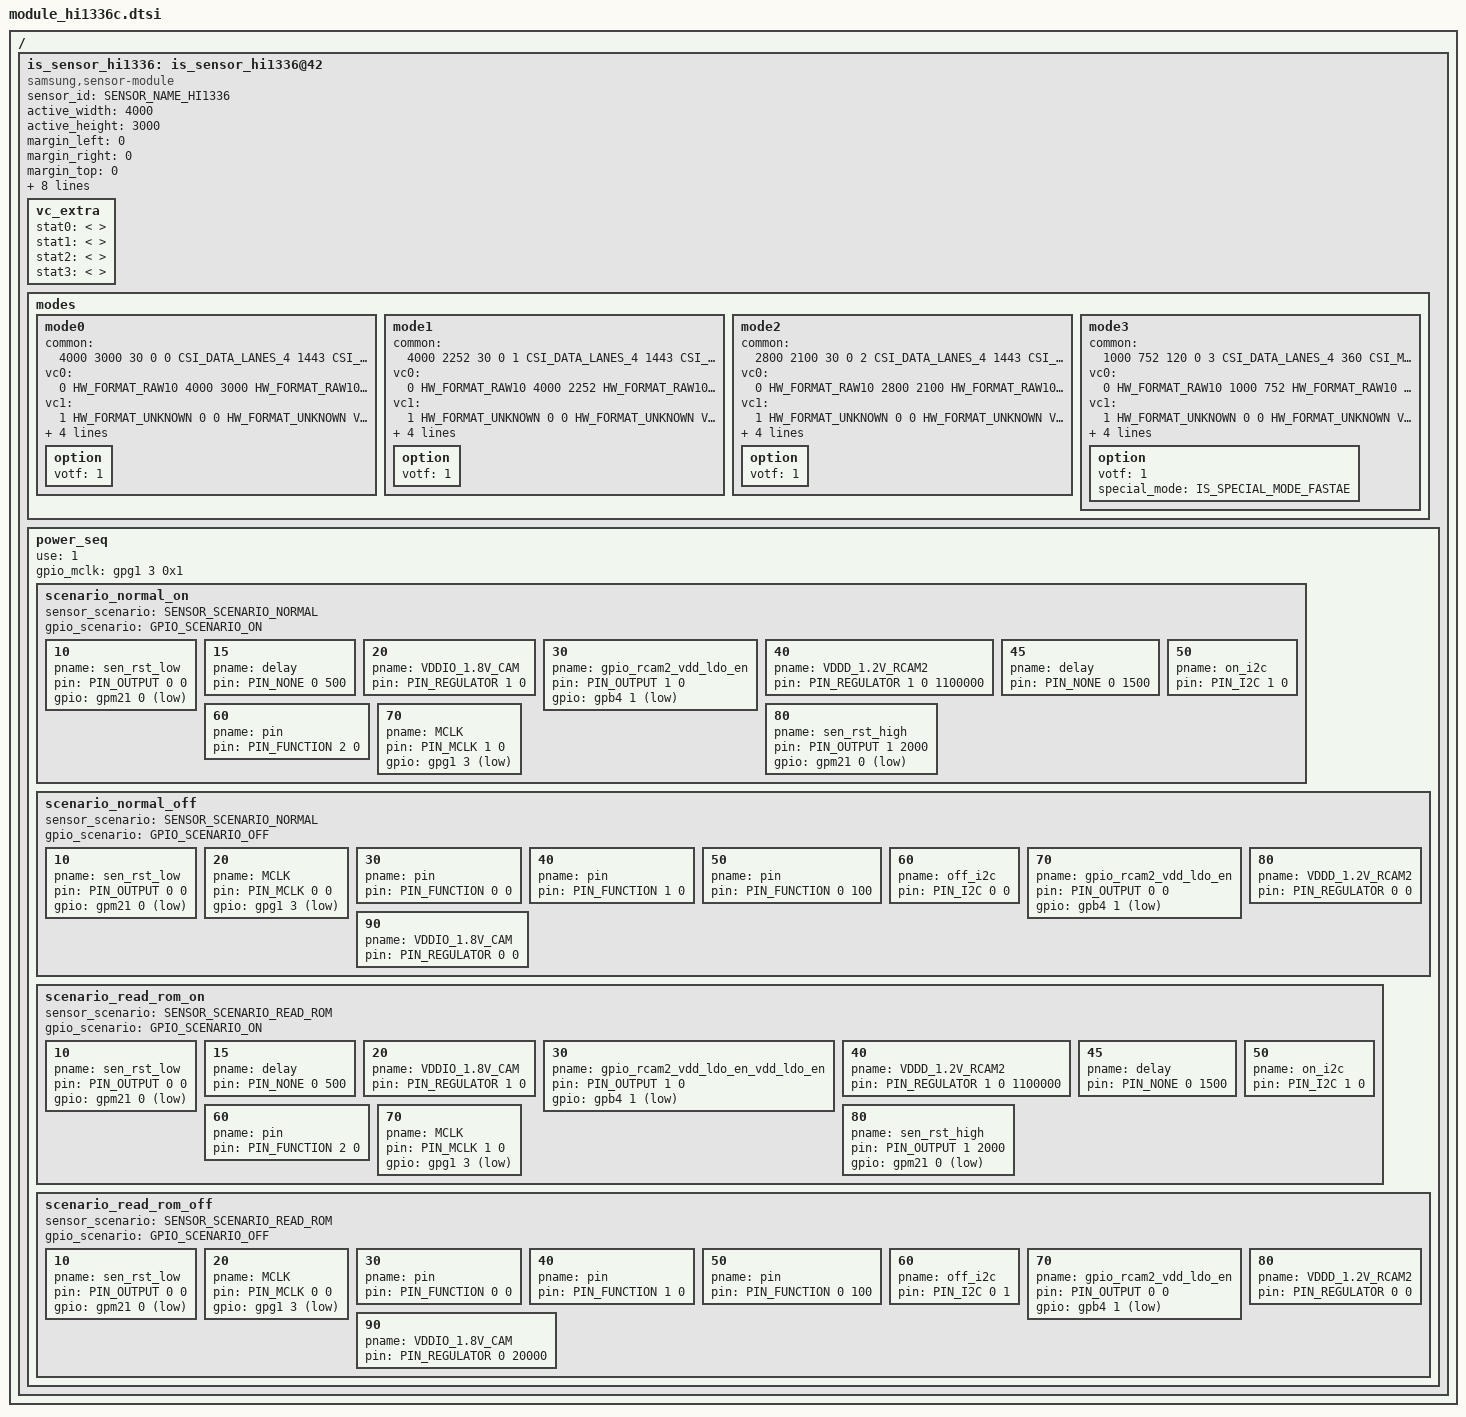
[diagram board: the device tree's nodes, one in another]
/*
 * SAMSUNG EXYNOSxxxx board camera device tree source
 *
 * Copyright (c) 2019 Samsung Electronics Co., Ltd.
 *		http://www.samsung.com
 *
 * This program is free software; you can redistribute it and/or modify
 * it under the terms of the GNU General Public License version 2 as
 * published by the Free Software Foundation.
 */

#include <dt-bindings/camera/exynos_is_dt.h>

/ {
	fragment@camera {
		target-path = "/";
		__overlay__ {
			is_sensor_hi1336: is_sensor_hi1336@42 {
				compatible = "samsung,sensor-module";

				/* common */
				sensor_id = <SENSOR_NAME_HI1336>;
				active_width = <4000>;
				active_height = <3000>;
				margin_left = <0>;
				margin_right = <0>;
				margin_top = <0>;
				margin_bottom = <0>;
				max_framerate = <120>;
				bitwidth = <10>;
				use_retention_mode = <SENSOR_RETENTION_UNSUPPORTED>;
				sensor_maker = "HYNIX";
				sensor_name = "HI1336";
				setfile_name = "setfile_hi1336.bin";

				status = "okay";

				vc_extra {
					/* ex) statX = <stat_type, sensor_mode, max_width, max_height, max_element> */
					stat0 = </* not avaliable */>;	/* VC_BUF_DATA_TYPE_SENSOR_STAT1 */
					stat1 = </* not avaliable */>;	/* VC_BUF_DATA_TYPE_GENERAL_STAT1 */
					stat2 = </* not avaliable */>;	/* VC_BUF_DATA_TYPE_SENSOR_STAT2 */
					stat3 = </* not avaliable */>;	/* VC_BUF_DATA_TYPE_GENERAL_STAT2 */
				};

				/*
				 * [Mode Information]
				 *
				 *  - Global setting
				 *
				 *
				 *  - Default Mode setting For HI1336B
				 *  [ 0 ] 4000 x 3000(4:3)      @30,  MIPI lane: 4, MIPI data rate(Mbps/lane):   1443, Mclk(Mhz): 26
				 *  [ 1 ] 4000 x 2252(16:9)     @30,  MIPI lane: 4, MIPI data rate(Mbps/lane):   1443, Mclk(Mhz): 26
				 *  [ 2 ] 2800 x 2100(4:3)      @30,  MIPI lane: 4, MIPI data rate(Mbps/lane):   1443, Mclk(Mhz): 26
				 *
				 *  [ 3 ] 1000 x 752(4:3)       @120, MIPI lane: 4, MIPI data rate(Mbps/lane): 360.75, Mclk(Mhz): 26
				 *
				 *  - Fsync setting
				 *  [ 0 ] Normal
				 *  [ 1 ] Slave
				 *  [ 2 ] Master full
				 *  [ 3 ] Master 2-binnig
				 *  [ 4 ] Master 4-binning
				 *
				 */

				/* sensor modes */
				modes {
						/* common = <width, height, fps, settle, mode, lane, speed, interleave, lrte, pd_mode> */
						/* vcX = <map, hwformat, width, height, hwformat, type, width, height> */
					/* Full Crop(4000x3000) 4:3 */
					mode0 {
						common = <4000 3000 30 0 0 CSI_DATA_LANES_4 1443 CSI_MODE_CH0_ONLY LRTE_DISABLE PD_NONE EX_NONE>;
						vc0 = </* in */ 0 HW_FORMAT_RAW10 4000 3000	/* out */ HW_FORMAT_RAW10 VC_NOTHING 4000 3000>;
						vc1 = </* in */ 1 HW_FORMAT_UNKNOWN 0 0		/* out */ HW_FORMAT_UNKNOWN VC_NOTHING 0 0>;
						vc2 = </* in */ 2 HW_FORMAT_UNKNOWN 0 0		/* out */ HW_FORMAT_UNKNOWN VC_NOTHING 0 0>;
						vc3 = </* in */ 3 HW_FORMAT_UNKNOWN 0 0		/* out */ HW_FORMAT_UNKNOWN VC_NOTHING 0 0>;
						option { votf = <1>; };
					};

					/* Full Crop(4000x2252) 16:9 */
					mode1 {
						common = <4000 2252 30 0 1 CSI_DATA_LANES_4 1443 CSI_MODE_CH0_ONLY LRTE_DISABLE PD_NONE EX_NONE>;
						vc0 = <0 HW_FORMAT_RAW10 4000 2252	/* out */ HW_FORMAT_RAW10 VC_NOTHING 4000 2252>;
						vc1 = <1 HW_FORMAT_UNKNOWN 0 0		/* out */ HW_FORMAT_UNKNOWN VC_NOTHING 0 0>;
						vc2 = <2 HW_FORMAT_UNKNOWN 0 0		/* out */ HW_FORMAT_UNKNOWN VC_NOTHING 0 0>;
						vc3 = <3 HW_FORMAT_UNKNOWN 0 0		/* out */ HW_FORMAT_UNKNOWN VC_NOTHING 0 0>;
						option { votf = <1>; };
					};

					/* Full Crop(2800x2100) 4:3 */
					mode2 {
						common = <2800 2100 30 0 2 CSI_DATA_LANES_4 1443 CSI_MODE_CH0_ONLY LRTE_DISABLE PD_NONE EX_NONE>;
						vc0 = <0 HW_FORMAT_RAW10 2800 2100	/* out */ HW_FORMAT_RAW10 VC_NOTHING 2800 2100>;
						vc1 = <1 HW_FORMAT_UNKNOWN 0 0		/* out */ HW_FORMAT_UNKNOWN VC_NOTHING 0 0>;
						vc2 = <2 HW_FORMAT_UNKNOWN 0 0		/* out */ HW_FORMAT_UNKNOWN VC_NOTHING 0 0>;
						vc3 = <3 HW_FORMAT_UNKNOWN 0 0		/* out */ HW_FORMAT_UNKNOWN VC_NOTHING 0 0>;
						option { votf = <1>; };
					};

					/* 4-binning */
					mode3 {
						common = <1000 752 120 0 3 CSI_DATA_LANES_4 360 CSI_MODE_CH0_ONLY LRTE_DISABLE PD_NONE EX_NONE>;
						vc0 = <0 HW_FORMAT_RAW10 1000 752	/* out */ HW_FORMAT_RAW10 VC_NOTHING 1000 752>;
						vc1 = <1 HW_FORMAT_UNKNOWN 0 0		/* out */ HW_FORMAT_UNKNOWN VC_NOTHING 0 0>;
						vc2 = <2 HW_FORMAT_UNKNOWN 0 0		/* out */ HW_FORMAT_UNKNOWN VC_NOTHING 0 0>;
						vc3 = <3 HW_FORMAT_UNKNOWN 0 0		/* out */ HW_FORMAT_UNKNOWN VC_NOTHING 0 0>;
						option { votf = <1>; special_mode = <IS_SPECIAL_MODE_FASTAE>; };
					};
				};

				power_seq {
					use = <1>;
					gpio_mclk = <&gpg1 3 0x1>;

					scenario_normal_on {
						sensor_scenario = <SENSOR_SCENARIO_NORMAL>;
						gpio_scenario = <GPIO_SCENARIO_ON>;

						/* A start node number should be over the 10 for reserved number 0~9. */
						/* pname = "name"; pin = <act value dealy voltage>; gpio = <gpx# # 0x1>; */
						10 { pname = "sen_rst_low"; pin = <PIN_OUTPUT 0 0>; gpio = <&gpm21 0 0x1>; };
						15 { pname = "delay"; pin = <PIN_NONE 0 500>; };
						20 { pname = "VDDIO_1.8V_CAM"; pin = <PIN_REGULATOR 1 0>; };
						30 { pname = "gpio_rcam2_vdd_ldo_en"; pin = <PIN_OUTPUT 1 0>; gpio = <&gpb4 1 0x1>; };
						40 { pname = "VDDD_1.2V_RCAM2"; pin = <PIN_REGULATOR 1 0 1100000>; };
						45 { pname = "delay"; pin = <PIN_NONE 0 1500>; };
						50 { pname = "on_i2c"; pin = <PIN_I2C 1 0>; };
						60 { pname = "pin"; pin = <PIN_FUNCTION 2 0>; };
						70 { pname = "MCLK"; pin = <PIN_MCLK 1 0>; gpio = <&gpg1 3 0x1>; };
						80 { pname = "sen_rst_high"; pin = <PIN_OUTPUT 1 2000>; gpio = <&gpm21 0 0x1>; };
					};

					scenario_normal_off {
						sensor_scenario = <SENSOR_SCENARIO_NORMAL>;
						gpio_scenario = <GPIO_SCENARIO_OFF>;

						/* A start node number should be over the 10 for reserved number 0~9. */
						/* pname = "name"; pin = <act value dealy voltage>; gpio = <gpx# # 0x1>; */
						10 { pname = "sen_rst_low"; pin = <PIN_OUTPUT 0 0>; gpio = <&gpm21 0 0x1>; };
						20 { pname = "MCLK"; pin = <PIN_MCLK 0 0>; gpio = <&gpg1 3 0x1>; };
						30 { pname = "pin"; pin = <PIN_FUNCTION 0 0>; };
						40 { pname = "pin"; pin = <PIN_FUNCTION 1 0>; };
						50 { pname = "pin"; pin = <PIN_FUNCTION 0 100>; };
						60 { pname = "off_i2c"; pin = <PIN_I2C 0 0>; };
						70 { pname = "gpio_rcam2_vdd_ldo_en"; pin = <PIN_OUTPUT 0 0>; gpio = <&gpb4 1 0x1>; };
						80 { pname = "VDDD_1.2V_RCAM2"; pin = <PIN_REGULATOR 0 0>; };
						90 { pname = "VDDIO_1.8V_CAM"; pin = <PIN_REGULATOR 0 0>; };
					};

					scenario_read_rom_on {
						sensor_scenario = <SENSOR_SCENARIO_READ_ROM>;
						gpio_scenario = <GPIO_SCENARIO_ON>;

						/* A start node number should be over the 10 for reserved number 0~9. */
						/* pname = "name"; pin = <act value dealy voltage>; gpio = <gpx# # 0x1>; */
						10 { pname = "sen_rst_low"; pin = <PIN_OUTPUT 0 0>; gpio = <&gpm21 0 0x1>; };
						15 { pname = "delay"; pin = <PIN_NONE 0 500>; };
						20 { pname = "VDDIO_1.8V_CAM"; pin = <PIN_REGULATOR 1 0>; };
						30 { pname = "gpio_rcam2_vdd_ldo_en_vdd_ldo_en"; pin = <PIN_OUTPUT 1 0>; gpio = <&gpb4 1 0x1>; };
						40 { pname = "VDDD_1.2V_RCAM2"; pin = <PIN_REGULATOR 1 0 1100000>; };
						45 { pname = "delay"; pin = <PIN_NONE 0 1500>; };
						50 { pname = "on_i2c"; pin = <PIN_I2C 1 0>; };
						60 { pname = "pin"; pin = <PIN_FUNCTION 2 0>; };
						70 { pname = "MCLK"; pin = <PIN_MCLK 1 0>; gpio = <&gpg1 3 0x1>; };
						80 { pname = "sen_rst_high"; pin = <PIN_OUTPUT 1 2000>; gpio = <&gpm21 0 0x1>; };
					};

					scenario_read_rom_off {
						sensor_scenario = <SENSOR_SCENARIO_READ_ROM>;
						gpio_scenario = <GPIO_SCENARIO_OFF>;

						/* A start node number should be over the 10 for reserved number 0~9. */
						/* pname = "name"; pin = <act value dealy voltage>; gpio = <gpx# # 0x1>; */
						10 { pname = "sen_rst_low"; pin = <PIN_OUTPUT 0 0>; gpio = <&gpm21 0 0x1>; };
						20 { pname = "MCLK"; pin = <PIN_MCLK 0 0>; gpio = <&gpg1 3 0x1>; };
						30 { pname = "pin"; pin = <PIN_FUNCTION 0 0>; };
						40 { pname = "pin"; pin = <PIN_FUNCTION 1 0>; };
						50 { pname = "pin"; pin = <PIN_FUNCTION 0 100>; };
						60 { pname = "off_i2c"; pin = <PIN_I2C 0 1>; };
						70 { pname = "gpio_rcam2_vdd_ldo_en"; pin = <PIN_OUTPUT 0 0>; gpio = <&gpb4 1 0x1>; };
						80 { pname = "VDDD_1.2V_RCAM2"; pin = <PIN_REGULATOR 0 0>; };
						90 { pname = "VDDIO_1.8V_CAM"; pin = <PIN_REGULATOR 0 20000>; };
					};
				};
			};
		}; /* end of __overlay__ */
	}; /* end of fragment */
}; /* end of root */
